AUTOSAR XML (schema 4-0-3)
package /ComponentTypes
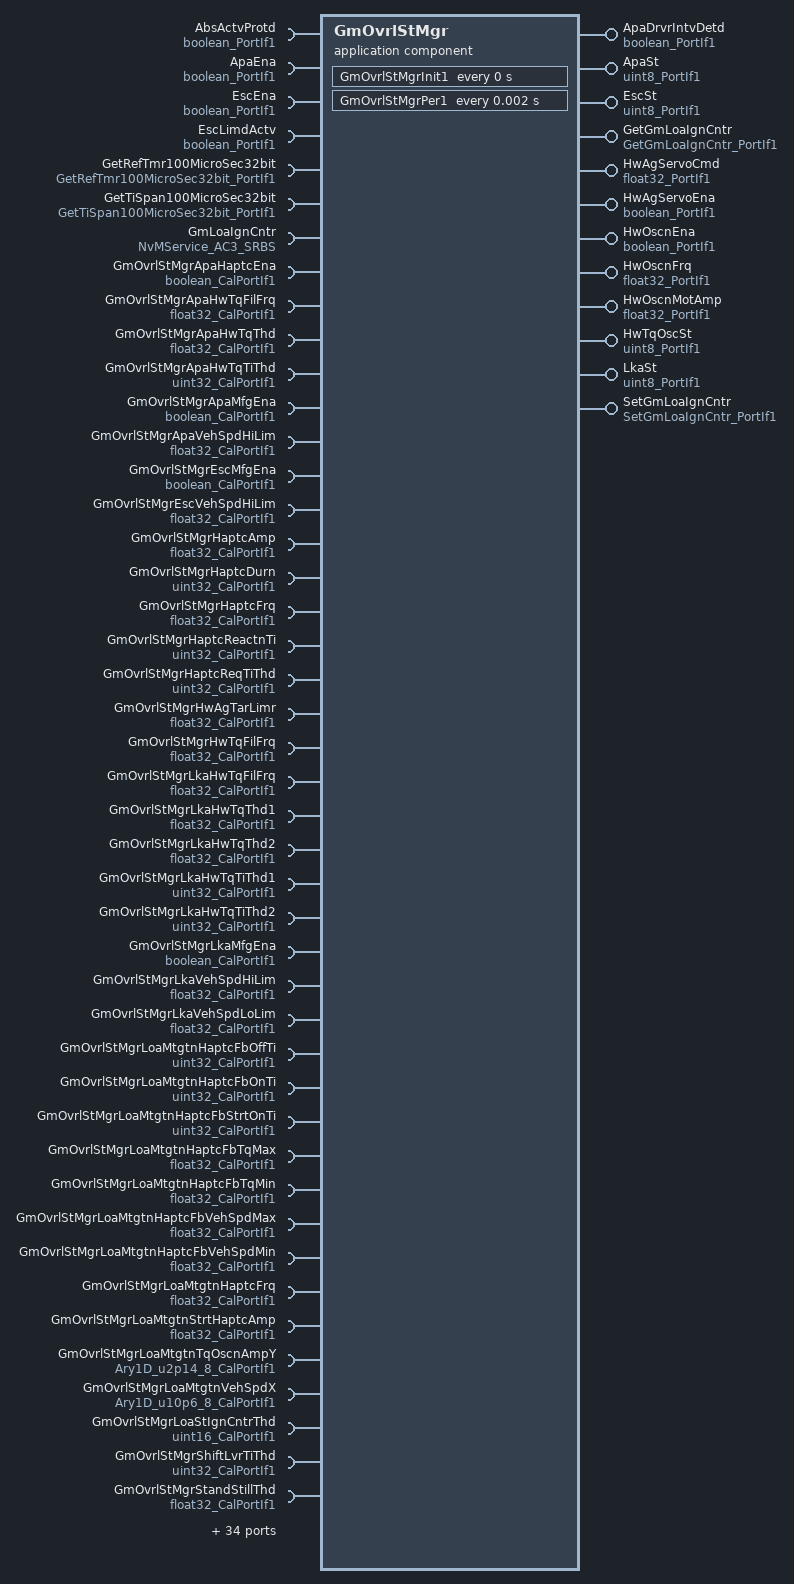
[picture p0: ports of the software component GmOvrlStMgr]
  application sw component type GmOvrlStMgr
    12 x provide port:
      ApaDrvrIntvDetd: nonqueued-sender-com-spec{data-element=Logl, init-value=0}, provided-interface=boolean_PortIf1
      ApaSt: nonqueued-sender-com-spec{data-element=Val, init-value=0}, provided-interface=uint8_PortIf1
      EscSt: nonqueued-sender-com-spec{data-element=Val, init-value=0}, provided-interface=uint8_PortIf1
      GetGmLoaIgnCntr: server-com-spec{operation=Oper, queue-length=1}, provided-interface=GetGmLoaIgnCntr_PortIf1
      HwAgServoCmd: nonqueued-sender-com-spec{data-element=Val, init-value=0}, provided-interface=float32_PortIf1
      HwAgServoEna: nonqueued-sender-com-spec{data-element=Logl, init-value=0}, provided-interface=boolean_PortIf1
      HwOscnEna: nonqueued-sender-com-spec{data-element=Logl, init-value=0}, provided-interface=boolean_PortIf1
      HwOscnFrq: nonqueued-sender-com-spec{data-element=Val, init-value=10}, provided-interface=float32_PortIf1
      HwOscnMotAmp: nonqueued-sender-com-spec{data-element=Val, init-value=0}, provided-interface=float32_PortIf1
      HwTqOscSt: nonqueued-sender-com-spec{data-element=Val, init-value=0}, provided-interface=uint8_PortIf1
      LkaSt: nonqueued-sender-com-spec{data-element=Val, init-value=0}, provided-interface=uint8_PortIf1
      SetGmLoaIgnCntr: server-com-spec{operation=Oper, queue-length=1}, provided-interface=SetGmLoaIgnCntr_PortIf1
    78 x require port:
      AbsActvProtd: nonqueued-receiver-com-spec{data-element=Logl, filter=data-filter-type=ALWAYS, init-value=0}, required-interface=boolean_PortIf1
      ApaEna: nonqueued-receiver-com-spec{data-element=Logl, filter=data-filter-type=ALWAYS, init-value=0}, required-interface=boolean_PortIf1
      EscEna: nonqueued-receiver-com-spec{data-element=Logl, filter=data-filter-type=ALWAYS, init-value=0}, required-interface=boolean_PortIf1
      EscLimdActv: nonqueued-receiver-com-spec{data-element=Logl, filter=data-filter-type=ALWAYS, init-value=0}, required-interface=boolean_PortIf1
      GetRefTmr100MicroSec32bit: required-interface=GetRefTmr100MicroSec32bit_PortIf1
      GetTiSpan100MicroSec32bit: required-interface=GetTiSpan100MicroSec32bit_PortIf1
      GmLoaIgnCntr: required-interface=NvMService_AC3_SRBS
      GmOvrlStMgrApaHaptcEna: parameter-require-com-spec{init-value=1, parameter=Logl}, required-interface=boolean_CalPortIf1
      GmOvrlStMgrApaHwTqFilFrq: parameter-require-com-spec{init-value=10, parameter=Val}, required-interface=float32_CalPortIf1
      GmOvrlStMgrApaHwTqThd: parameter-require-com-spec{init-value=3, parameter=Val}, required-interface=float32_CalPortIf1
      GmOvrlStMgrApaHwTqTiThd: parameter-require-com-spec{init-value=50, parameter=Val}, required-interface=uint32_CalPortIf1
      GmOvrlStMgrApaMfgEna: parameter-require-com-spec{init-value=0, parameter=Logl}, required-interface=boolean_CalPortIf1
      GmOvrlStMgrApaVehSpdHiLim: parameter-require-com-spec{init-value=10, parameter=Val}, required-interface=float32_CalPortIf1
      GmOvrlStMgrEscMfgEna: parameter-require-com-spec{init-value=0, parameter=Logl}, required-interface=boolean_CalPortIf1
      GmOvrlStMgrEscVehSpdHiLim: parameter-require-com-spec{init-value=180, parameter=Val}, required-interface=float32_CalPortIf1
      GmOvrlStMgrHaptcAmp: parameter-require-com-spec{init-value=0.5, parameter=Val}, required-interface=float32_CalPortIf1
      GmOvrlStMgrHaptcDurn: parameter-require-com-spec{init-value=450, parameter=Val}, required-interface=uint32_CalPortIf1
      GmOvrlStMgrHaptcFrq: parameter-require-com-spec{init-value=10, parameter=Val}, required-interface=float32_CalPortIf1
      GmOvrlStMgrHaptcReactnTi: parameter-require-com-spec{init-value=350, parameter=Val}, required-interface=uint32_CalPortIf1
      GmOvrlStMgrHaptcReqTiThd: parameter-require-com-spec{init-value=500, parameter=Val}, required-interface=uint32_CalPortIf1
      GmOvrlStMgrHwAgTarLimr: parameter-require-com-spec{init-value=30, parameter=Val}, required-interface=float32_CalPortIf1
      GmOvrlStMgrHwTqFilFrq: parameter-require-com-spec{init-value=10, parameter=Val}, required-interface=float32_CalPortIf1
      GmOvrlStMgrLkaHwTqFilFrq: parameter-require-com-spec{init-value=10, parameter=Val}, required-interface=float32_CalPortIf1
      GmOvrlStMgrLkaHwTqThd1: parameter-require-com-spec{init-value=3, parameter=Val}, required-interface=float32_CalPortIf1
      GmOvrlStMgrLkaHwTqThd2: parameter-require-com-spec{init-value=5, parameter=Val}, required-interface=float32_CalPortIf1
      GmOvrlStMgrLkaHwTqTiThd1: parameter-require-com-spec{init-value=10000, parameter=Val}, required-interface=uint32_CalPortIf1
      GmOvrlStMgrLkaHwTqTiThd2: parameter-require-com-spec{init-value=100, parameter=Val}, required-interface=uint32_CalPortIf1
      GmOvrlStMgrLkaMfgEna: parameter-require-com-spec{init-value=0, parameter=Logl}, required-interface=boolean_CalPortIf1
      GmOvrlStMgrLkaVehSpdHiLim: parameter-require-com-spec{init-value=180, parameter=Val}, required-interface=float32_CalPortIf1
      GmOvrlStMgrLkaVehSpdLoLim: parameter-require-com-spec{init-value=10, parameter=Val}, required-interface=float32_CalPortIf1
      GmOvrlStMgrLoaMtgtnHaptcFbOffTi: parameter-require-com-spec{init-value=5000, parameter=Val}, required-interface=uint32_CalPortIf1
      GmOvrlStMgrLoaMtgtnHaptcFbOnTi: parameter-require-com-spec{init-value=800, parameter=Val}, required-interface=uint32_CalPortIf1
      GmOvrlStMgrLoaMtgtnHaptcFbStrtOnTi: parameter-require-com-spec{init-value=2000, parameter=Val}, required-interface=uint32_CalPortIf1
      GmOvrlStMgrLoaMtgtnHaptcFbTqMax: parameter-require-com-spec{init-value=8, parameter=Val}, required-interface=float32_CalPortIf1
      GmOvrlStMgrLoaMtgtnHaptcFbTqMin: parameter-require-com-spec{init-value=0.5, parameter=Val}, required-interface=float32_CalPortIf1
      GmOvrlStMgrLoaMtgtnHaptcFbVehSpdMax: parameter-require-com-spec{init-value=128, parameter=Val}, required-interface=float32_CalPortIf1
      GmOvrlStMgrLoaMtgtnHaptcFbVehSpdMin: parameter-require-com-spec{init-value=2, parameter=Val}, required-interface=float32_CalPortIf1
      GmOvrlStMgrLoaMtgtnHaptcFrq: parameter-require-com-spec{init-value=10, parameter=Val}, required-interface=float32_CalPortIf1
      GmOvrlStMgrLoaMtgtnStrtHaptcAmp: parameter-require-com-spec{init-value=0.2, parameter=Val}, required-interface=float32_CalPortIf1
      GmOvrlStMgrLoaMtgtnTqOscnAmpY: parameter-require-com-spec{init-value=8 x 8192, parameter=Ary1D}, required-interface=Ary1D_u2p14_8_CalPortIf1
      GmOvrlStMgrLoaMtgtnVehSpdX: parameter-require-com-spec{init-value=[320, 640, 1280, 2560, 3840, 5120, 6400, 7680], parameter=Ary1D}, required-interface=Ary1D_u10p6_8_CalPortIf1
      GmOvrlStMgrLoaStIgnCntrThd: parameter-require-com-spec{init-value=20, parameter=Val}, required-interface=uint16_CalPortIf1
      GmOvrlStMgrShiftLvrTiThd: parameter-require-com-spec{init-value=200, parameter=Val}, required-interface=uint32_CalPortIf1
      GmOvrlStMgrStandStillThd: parameter-require-com-spec{init-value=2.5, parameter=Val}, required-interface=float32_CalPortIf1
      GmOvrlStMgrStandStillTiThd: parameter-require-com-spec{init-value=250, parameter=Val}, required-interface=uint32_CalPortIf1
      HwAgEotCcw: nonqueued-receiver-com-spec{data-element=Val, filter=data-filter-type=ALWAYS, init-value=-360}, required-interface=float32_PortIf1
      HwAgEotCw: nonqueued-receiver-com-spec{data-element=Val, filter=data-filter-type=ALWAYS, init-value=360}, required-interface=float32_PortIf1
      HwAgTar: nonqueued-receiver-com-spec{data-element=Val, filter=data-filter-type=ALWAYS, init-value=0}, required-interface=float32_PortIf1
      HwAgTraj: nonqueued-receiver-com-spec{data-element=Val, filter=data-filter-type=ALWAYS, init-value=0}, required-interface=float32_PortIf1
      HwAgTrajEna: nonqueued-receiver-com-spec{data-element=Logl, filter=data-filter-type=ALWAYS, init-value=0}, required-interface=boolean_PortIf1
      HwHaptcEna: nonqueued-receiver-com-spec{data-element=Logl, filter=data-filter-type=ALWAYS, init-value=0}, required-interface=boolean_PortIf1
      HwTq: nonqueued-receiver-com-spec{data-element=Val, filter=data-filter-type=ALWAYS, init-value=0}, required-interface=float32_PortIf1
      LkaEna: nonqueued-receiver-com-spec{data-element=Logl, filter=data-filter-type=ALWAYS, init-value=0}, required-interface=boolean_PortIf1
      LkaTqCmdCdnd: nonqueued-receiver-com-spec{data-element=Val, filter=data-filter-type=ALWAYS, init-value=0}, required-interface=float32_PortIf1
      LoaSt: nonqueued-receiver-com-spec{data-element=Val, filter=data-filter-type=ALWAYS, init-value=0}, required-interface=LoaSt1_PortIf1
      MfgOvrlDi: nonqueued-receiver-com-spec{data-element=Logl, filter=data-filter-type=ALWAYS, init-value=0}, required-interface=boolean_PortIf1
      Msg17DBusHiSpdInvld: nonqueued-receiver-com-spec{data-element=Logl, filter=data-filter-type=ALWAYS, init-value=0}, required-interface=boolean_PortIf1
      Msg17DBusHiSpdMiss: nonqueued-receiver-com-spec{data-element=Logl, filter=data-filter-type=ALWAYS, init-value=0}, required-interface=boolean_PortIf1
      Msg180BusChassisExpInvld: nonqueued-receiver-com-spec{data-element=Logl, filter=data-filter-type=ALWAYS, init-value=0}, required-interface=boolean_PortIf1
      Msg180BusChassisExpMiss: nonqueued-receiver-com-spec{data-element=Logl, filter=data-filter-type=ALWAYS, init-value=0}, required-interface=boolean_PortIf1
      Msg180BusHiSpdInvld: nonqueued-receiver-com-spec{data-element=Logl, filter=data-filter-type=ALWAYS, init-value=0}, required-interface=boolean_PortIf1
      Msg180BusHiSpdMiss: nonqueued-receiver-com-spec{data-element=Logl, filter=data-filter-type=ALWAYS, init-value=0}, required-interface=boolean_PortIf1
      Msg1E9BusHiSpdInvld: nonqueued-receiver-com-spec{data-element=Logl, filter=data-filter-type=ALWAYS, init-value=0}, required-interface=boolean_PortIf1
      Msg1E9BusHiSpdMiss: nonqueued-receiver-com-spec{data-element=Logl, filter=data-filter-type=ALWAYS, init-value=0}, required-interface=boolean_PortIf1
      Msg1F5BusHiSpdInvld: nonqueued-receiver-com-spec{data-element=Logl, filter=data-filter-type=ALWAYS, init-value=0}, required-interface=boolean_PortIf1
      Msg214BusHiSpdInvld: nonqueued-receiver-com-spec{data-element=Logl, filter=data-filter-type=ALWAYS, init-value=0}, required-interface=boolean_PortIf1
      Msg214BusHiSpdMiss: nonqueued-receiver-com-spec{data-element=Logl, filter=data-filter-type=ALWAYS, init-value=0}, required-interface=boolean_PortIf1
      Msg337BusChassisExpInvld: nonqueued-receiver-com-spec{data-element=Logl, filter=data-filter-type=ALWAYS, init-value=0}, required-interface=boolean_PortIf1
      Msg337BusChassisExpMiss: nonqueued-receiver-com-spec{data-element=Logl, filter=data-filter-type=ALWAYS, init-value=0}, required-interface=boolean_PortIf1
      SetNtcSts: required-interface=SetNtcSts_PortIf1
      ShiftLvrRvs: nonqueued-receiver-com-spec{data-element=Logl, filter=data-filter-type=ALWAYS, init-value=0}, required-interface=boolean_PortIf1
      SysSt: nonqueued-receiver-com-spec{data-element=Val, filter=data-filter-type=ALWAYS, init-value=3}, required-interface=SysSt1_PortIf1
      VehSpd: nonqueued-receiver-com-spec{data-element=Val, filter=data-filter-type=ALWAYS, init-value=0}, required-interface=float32_PortIf1
      VehSpdSecurMax: nonqueued-receiver-com-spec{data-element=Val, filter=data-filter-type=ALWAYS, init-value=0}, required-interface=float32_PortIf1
      VehSpdSecurMaxVld: nonqueued-receiver-com-spec{data-element=Logl, filter=data-filter-type=ALWAYS, init-value=0}, required-interface=boolean_PortIf1
      VehSpdSecurMin: nonqueued-receiver-com-spec{data-element=Val, filter=data-filter-type=ALWAYS, init-value=0}, required-interface=float32_PortIf1
      VehSpdSecurMinVld: nonqueued-receiver-com-spec{data-element=Logl, filter=data-filter-type=ALWAYS, init-value=0}, required-interface=boolean_PortIf1
      VehStabyEnhmtActv: nonqueued-receiver-com-spec{data-element=Logl, filter=data-filter-type=ALWAYS, init-value=0}, required-interface=boolean_PortIf1
    behavior GmOvrlStMgr_InternalBehavior
      ar-typed-per-instance-memorys:
        33 x data, all with sw-calibration-access=READ-ONLY:
          dGmOvrlStMgrApaShiftLvrRvs: type=boolean
          dGmOvrlStMgrApaStandStill: type=boolean
          GmLoaIgnCntr: type=uint16
          HaptcStTranActvToWaitRefTi: type=uint32
          HapticActvRefTmr: type=uint32
          HapticWaitRefTmr: type=uint32
          HwTqLkaLpFil: type=FilLpRec1
          HwTqLpFil: type=FilLpRec1
          HwTqOscnLpFil: type=FilLpRec1
          IgnCntrUpd: type=boolean
          LkaFltCntr: type=uint8
          LkaFltPrev: type=boolean
          LkaFltRefTmr: type=uint32
          LkaIntvPrev: type=boolean
          LkaIntvRefTi1: type=uint32
          LkaIntvRefTi2: type=uint32
          LoaMtgtnHaptcFbStrtOnRefTi: type=uint32
          LoaStChk: type=boolean
          PrevApaIntvEna: type=boolean
          PrevApaIntvRefTi: type=uint32
          PrevApaSt: type=uint8
          PrevEscSt: type=uint8
          PrevHaptcReqEna: type=boolean
          PrevHaptcReqRefTi: type=uint32
          PrevHaptcSt: type=uint8
          PrevLkaFlt: type=boolean
          PrevLkaSt: type=uint8
          PrevShiftLvrRvsEna: type=boolean
          PrevShiftLvrRvsRefTi: type=uint32
          PrevVehStandStillEna: type=boolean
          PrevVehStandStillRefTi: type=uint32
          TqOscCycRefTi: type=uint32
          TranHaptcWaitToApaStActvRefTi: type=uint32
      operation invoked event OIT_GetGmLoaIgnCntr_Oper_GetGmLoaIgnCntr_Oper: start-on-event=GetGmLoaIgnCntr_Oper, operation=GetGmLoaIgnCntr.Oper
      timing event GmOvrlStMgr_InitEvent: start-on-event=GmOvrlStMgrInit1, period=0
      timing event TMT_GmOvrlStMgrPer1: start-on-event=GmOvrlStMgrPer1, period=0.002
      operation invoked event OIT_SetGmLoaIgnCntr_Oper_SetGmLoaIgnCntr_Oper: start-on-event=SetGmLoaIgnCntr_Oper, operation=SetGmLoaIgnCntr.Oper
      explicit-inter-runnable-variables:
        data IgnCntrLcl: type=uint16, init-value=0
      4 x runnable:
        GetGmLoaIgnCntr_Oper
        GmOvrlStMgrInit1
          4 x sync call, all with timeout=0:
            SC_GetRefTmr100MicroSec32bit_Oper: operation=GetRefTmr100MicroSec32bit.Oper
            SC_GmLoaIgnCntr_GetErrorStatus: operation=GmLoaIgnCntr.GetErrorStatus
            SC_GmLoaIgnCntr_SetRamBlockStatus: operation=GmLoaIgnCntr.SetRamBlockStatus
            SC_SetNtcSts_Oper: operation=SetNtcSts.Oper
          written-local-variables:
            access WRITE_IgnCntrLcl: accessed-variable=IgnCntrLcl
        GmOvrlStMgrPer1
          data-receive-point-by-arguments:
            36 x access:
              REC_AbsActvProtd_Logl: accessed-variable=AbsActvProtd.Logl
              REC_ApaEna_Logl: accessed-variable=ApaEna.Logl
              REC_EscEna_Logl: accessed-variable=EscEna.Logl
              REC_EscLimdActv_Logl: accessed-variable=EscLimdActv.Logl
              REC_HwAgEotCcw_Val: accessed-variable=HwAgEotCcw.Val
              REC_HwAgEotCw_Val: accessed-variable=HwAgEotCw.Val
              REC_HwAgTar_Val: accessed-variable=HwAgTar.Val
              REC_HwAgTraj_Val: accessed-variable=HwAgTraj.Val
              REC_HwAgTrajEna_Logl: accessed-variable=HwAgTrajEna.Logl
              REC_HwHaptcEna_Logl: accessed-variable=HwHaptcEna.Logl
              REC_HwTq_Val: accessed-variable=HwTq.Val
              REC_LkaEna_Logl: accessed-variable=LkaEna.Logl
              REC_LkaTqCmdCdnd_Val: accessed-variable=LkaTqCmdCdnd.Val
              REC_LoaSt_Val: accessed-variable=LoaSt.Val
              REC_MfgOvrlDi_Logl: accessed-variable=MfgOvrlDi.Logl
              REC_Msg17DBusHiSpdInvld_Logl: accessed-variable=Msg17DBusHiSpdInvld.Logl
              REC_Msg17DBusHiSpdMiss_Logl: accessed-variable=Msg17DBusHiSpdMiss.Logl
              REC_Msg180BusChassisExpInvld_Logl: accessed-variable=Msg180BusChassisExpInvld.Logl
              REC_Msg180BusChassisExpMiss_Logl: accessed-variable=Msg180BusChassisExpMiss.Logl
              REC_Msg180BusHiSpdInvld_Logl: accessed-variable=Msg180BusHiSpdInvld.Logl
              REC_Msg180BusHiSpdMiss_Logl: accessed-variable=Msg180BusHiSpdMiss.Logl
              REC_Msg1E9BusHiSpdInvld_Logl: accessed-variable=Msg1E9BusHiSpdInvld.Logl
              REC_Msg1E9BusHiSpdMiss_Logl: accessed-variable=Msg1E9BusHiSpdMiss.Logl
              REC_Msg1F5BusHiSpdInvld_Logl: accessed-variable=Msg1F5BusHiSpdInvld.Logl
              REC_Msg214BusHiSpdInvld_Logl: accessed-variable=Msg214BusHiSpdInvld.Logl
              REC_Msg214BusHiSpdMiss_Logl: accessed-variable=Msg214BusHiSpdMiss.Logl
              REC_Msg337BusChassisExpInvld_Logl: accessed-variable=Msg337BusChassisExpInvld.Logl
              REC_Msg337BusChassisExpMiss_Logl: accessed-variable=Msg337BusChassisExpMiss.Logl
              REC_ShiftLvrRvs_Logl: accessed-variable=ShiftLvrRvs.Logl
              REC_SysSt_Val: accessed-variable=SysSt.Val
              REC_VehSpd_Val: accessed-variable=VehSpd.Val
              REC_VehSpdSecurMax_Val: accessed-variable=VehSpdSecurMax.Val
              REC_VehSpdSecurMaxVld_Logl: accessed-variable=VehSpdSecurMaxVld.Logl
              REC_VehSpdSecurMin_Val: accessed-variable=VehSpdSecurMin.Val
              REC_VehSpdSecurMinVld_Logl: accessed-variable=VehSpdSecurMinVld.Logl
              REC_VehStabyEnhmtActv_Logl: accessed-variable=VehStabyEnhmtActv.Logl
          data-send-points:
            10 x access:
              SEND_ApaDrvrIntvDetd_Logl: accessed-variable=ApaDrvrIntvDetd.Logl
              SEND_ApaSt_Val: accessed-variable=ApaSt.Val
              SEND_EscSt_Val: accessed-variable=EscSt.Val
              SEND_HwAgServoCmd_Val: accessed-variable=HwAgServoCmd.Val
              SEND_HwAgServoEna_Logl: accessed-variable=HwAgServoEna.Logl
              SEND_HwTqOscAmp_Val: accessed-variable=HwOscnFrq.Val
              SEND_HwTqOscEna_Logl: accessed-variable=HwOscnEna.Logl
              SEND_HwTqOscFrq_Val: accessed-variable=HwOscnMotAmp.Val
              SEND_HwTqOscSt_Val: accessed-variable=HwTqOscSt.Val
              SEND_LkaSt_Val: accessed-variable=LkaSt.Val
          read-local-variables:
            access READ_IgnCntrLcl: accessed-variable=IgnCntrLcl
          sync call SC_GetRefTmr100MicroSec32bit_Oper: operation=GetRefTmr100MicroSec32bit.Oper, timeout=0
          sync call SC_GetTiSpan100MicroSec32bit_Oper: operation=GetTiSpan100MicroSec32bit.Oper, timeout=0
          sync call SC_GmLoaIgnCntr_SetRamBlockStatus: operation=GmLoaIgnCntr.SetRamBlockStatus, timeout=0
        SetGmLoaIgnCntr_Oper
          sync call SC_GmLoaIgnCntr_SetRamBlockStatus: operation=GmLoaIgnCntr.SetRamBlockStatus, timeout=0
      swc service dependency NvmGmLoaIgnCntr: assigned-datas=role-based-data-assignment={role=ramBlock, used-data-element=GmLoaIgnCntr}
        assigned-ports:
          port-prototype=GmLoaIgnCntr, role=NvMService_AC3_SRBS
          port-prototype=GmLoaIgnCntr, role=NvMService_AC3_SRBS
        service-needs:
          nv block needs NvmGmLoaIgnCntr: n-data-sets=0, readonly=false, reliability=ERROR-DETECTION, resistant-to-changed-sw=true, restore-at-start=true, store-at-shutdown=true, write-only-once=false, writing-frequency=0, writing-priority=LOW
  swc implementation GmOvrlStMgr_Implementation: behavior=GmOvrlStMgr_InternalBehavior
    code-descriptors:
      code Default: artifact-descriptors=autosar-engineering-object={short-label=Default, category=SWSRC}
